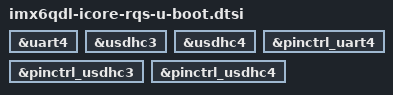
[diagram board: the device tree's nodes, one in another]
// SPDX-License-Identifier: GPL-2.0+
/*
 * Copyright (C) 2018 Jagan Teki <jagan@amarulasolutions.com>
 */

#include "imx6qdl-u-boot.dtsi"

&uart4 {
	u-boot,dm-spl;
};

&usdhc3 {
	u-boot,dm-spl;
};

&usdhc4 {
	u-boot,dm-spl;
};

&pinctrl_uart4 {
	u-boot,dm-spl;
};

&pinctrl_usdhc3 {
	u-boot,dm-spl;
};

&pinctrl_usdhc4 {
	u-boot,dm-spl;
};
